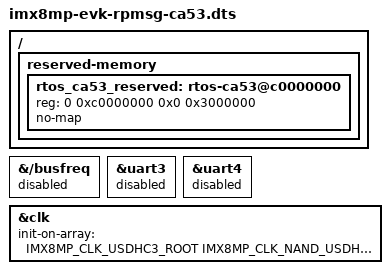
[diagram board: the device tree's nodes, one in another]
// SPDX-License-Identifier: (GPL-2.0 OR MIT)
/*
 * Copyright 2024 NXP
 */

/dts-v1/;

#include "imx8mp-evk.dts"
#include "imx8mp-rpmsg-ca53.dtsi"
#include "imx8m-rproc-ca53.dtsi"

/ {
	reserved-memory {
		#address-cells = <2>;
		#size-cells = <2>;
		ranges;

		rtos_ca53_reserved: rtos-ca53@c0000000 {
			reg = <0 0xc0000000 0x0 0x3000000>;
			no-map;
		};

	};
};

&{/busfreq} {
	/* Disable busfreq to avoid Linux busfreq crash multicore virtio backend */
	status = "disabled";
};

&uart3 {
	status = "disabled";
};

&uart4 {
	status = "disabled";
};

&clk {
	init-on-array = <IMX8MP_CLK_USDHC3_ROOT
			 IMX8MP_CLK_NAND_USDHC_BUS
			 IMX8MP_CLK_HSIO_ROOT
			 IMX8MP_CLK_UART3_ROOT
			 IMX8MP_CLK_UART4_ROOT>;
};
